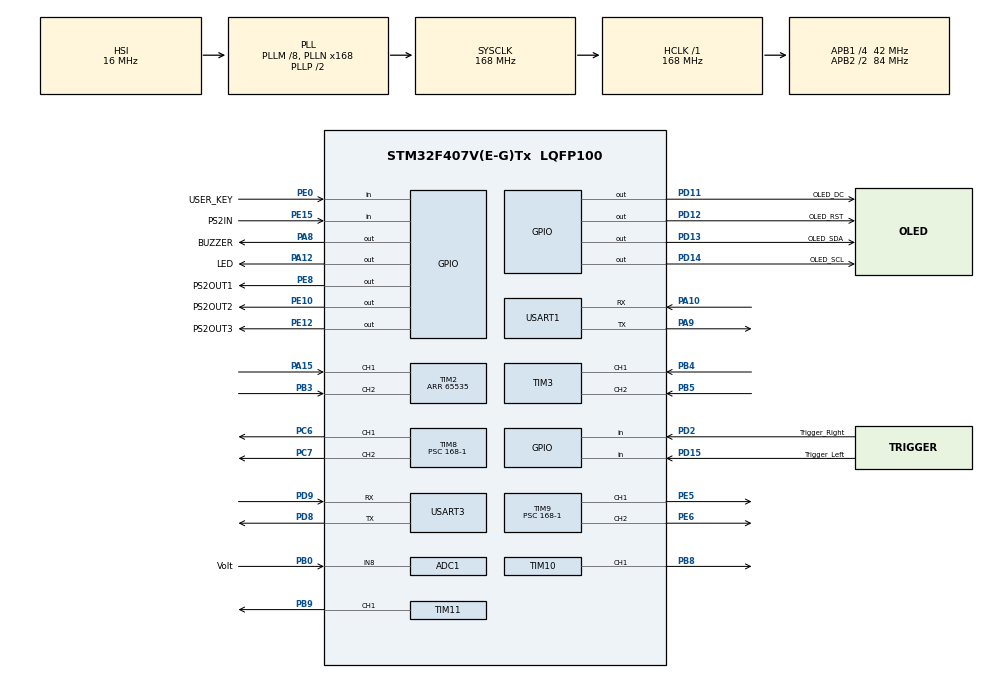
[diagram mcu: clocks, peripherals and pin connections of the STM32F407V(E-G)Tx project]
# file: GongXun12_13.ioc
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ADC1.Channel-0\#ChannelRegularConversion=ADC_CHANNEL_8
ADC1.Channel-1\#ChannelInjectedConversion=ADC_CHANNEL_8
ADC1.ContinuousConvMode=ENABLE
ADC1.InjNumberOfConversion=1
ADC1.InjectedOffset-1\#ChannelInjectedConversion=0
ADC1.InjectedRank-1\#ChannelInjectedConversion=1
ADC1.NbrOfConversion=1
ADC1.NbrOfConversionFlag=1
ADC1.Rank-0\#ChannelRegularConversion=1
ADC1.SamplingTime-0\#ChannelRegularConversion=ADC_SAMPLETIME_3CYCLES
ADC1.SamplingTime-1\#ChannelInjectedConversion=ADC_SAMPLETIME_3CYCLES
ADC1.master=1
Mcu.Family=STM32F4
Mcu.Name=STM32F407V(E-G)Tx
Mcu.Package=LQFP100
NVIC.PriorityGroup=NVIC_PRIORITYGROUP_4
NVIC.TIM1_UP_TIM10_IRQn=true\:15\:0\:false\:false\:true\:false\:true\:true
NVIC.TimeBase=TIM1_UP_TIM10_IRQn
NVIC.TimeBaseIP=TIM1
NVIC.USART1_IRQn=true\:0\:0\:false\:false\:true\:true\:true\:true
NVIC.USART3_IRQn=true\:0\:0\:false\:false\:true\:true\:true\:true
PA10.Mode=Asynchronous
PA10.Signal=USART1_RX
PA12.GPIO_Label=LED
PA12.Signal=GPIO_Output
PA13.Mode=Serial_Wire
PA13.Signal=SYS_JTMS-SWDIO
PA14.Mode=Serial_Wire
PA14.Signal=SYS_JTCK-SWCLK
PA15.Signal=S_TIM2_CH1_ETR
PA8.GPIO_Label=BUZZER
PA8.Signal=GPIO_Output
PA9.Mode=Asynchronous
PA9.Signal=USART1_TX
PB0.GPIO_Label=Volt
PB0.Signal=ADCx_IN8
PB3.Signal=S_TIM2_CH2
PB4.Signal=S_TIM3_CH1
PB5.Signal=S_TIM3_CH2
PB8.Signal=S_TIM10_CH1
PB9.Signal=S_TIM11_CH1
PC6.Signal=S_TIM8_CH1
PC7.Signal=S_TIM8_CH2
PD11.GPIO_Label=OLED_DC
PD11.Signal=GPIO_Output
PD12.GPIO_Label=OLED_RST
PD12.Signal=GPIO_Output
PD13.GPIO_Label=OLED_SDA
PD13.Signal=GPIO_Output
PD14.GPIO_Label=OLED_SCL
PD14.Signal=GPIO_Output
PD15.GPIO_Label=Trigger_Left
PD15.GPIO_PuPd=GPIO_PULLUP
PD15.Signal=GPIO_Input
PD2.GPIO_Label=Trigger_Right
PD2.GPIO_PuPd=GPIO_PULLUP
PD2.Signal=GPIO_Input
PD8.Mode=Asynchronous
PD8.Signal=USART3_TX
PD9.Mode=Asynchronous
PD9.Signal=USART3_RX
PE0.GPIO_Label=USER_KEY
PE0.Signal=GPIO_Input
PE10.GPIO_Label=PS2OUT2
PE10.GPIO_PuPd=GPIO_PULLUP
PE10.GPIO_Speed=GPIO_SPEED_FREQ_HIGH
PE10.Signal=GPIO_Output
PE12.GPIO_Label=PS2OUT3
PE12.GPIO_PuPd=GPIO_PULLUP
PE12.GPIO_Speed=GPIO_SPEED_FREQ_HIGH
PE12.Signal=GPIO_Output
PE15.GPIO_Label=PS2IN
PE15.GPIO_PuPd=GPIO_PULLDOWN
PE15.Signal=GPIO_Input
PE5.Signal=S_TIM9_CH1
PE6.Signal=S_TIM9_CH2
PE8.GPIO_Label=PS2OUT1
PE8.GPIO_PuPd=GPIO_PULLUP
PE8.GPIO_Speed=GPIO_SPEED_FREQ_HIGH
PE8.Signal=GPIO_Output
PH0-OSC_IN.Mode=HSE-External-Oscillator
PH0-OSC_IN.Signal=RCC_OSC_IN
PH1-OSC_OUT.Mode=HSE-External-Oscillator
PH1-OSC_OUT.Signal=RCC_OSC_OUT
ProjectManager.HeapSize=0x200
ProjectManager.StackSize=0x400
ProjectManager.TargetToolchain=CMake
RCC.48MHZClocksFreq_Value=84000000
RCC.AHBFreq_Value=168000000
RCC.APB1CLKDivider=RCC_HCLK_DIV4
RCC.APB1Freq_Value=42000000
RCC.APB1TimFreq_Value=84000000
RCC.APB2CLKDivider=RCC_HCLK_DIV2
RCC.APB2Freq_Value=84000000
RCC.APB2TimFreq_Value=168000000
RCC.CortexFreq_Value=168000000
RCC.HCLKFreq_Value=168000000
RCC.HSE_VALUE=25000000
RCC.HSI_VALUE=16000000
RCC.LSE_VALUE=32768
RCC.PLLM=8
RCC.PLLN=168
RCC.SYSCLKFreq_VALUE=168000000
RCC.SYSCLKSource=RCC_SYSCLKSOURCE_PLLCLK
RCC.VCOOutputFreq_Value=336000000
SH.ADCx_IN8.0=ADC1_IN8,IN8
SH.S_TIM10_CH1.0=TIM10_CH1,PWM Generation1 CH1
SH.S_TIM11_CH1.0=TIM11_CH1,PWM Generation1 CH1
SH.S_TIM2_CH1_ETR.0=TIM2_CH1,Encoder_Interface
SH.S_TIM2_CH2.0=TIM2_CH2,Encoder_Interface
SH.S_TIM3_CH1.0=TIM3_CH1,Encoder_Interface
SH.S_TIM3_CH2.0=TIM3_CH2,Encoder_Interface
SH.S_TIM8_CH1.0=TIM8_CH1,PWM Generation1 CH1
SH.S_TIM8_CH2.0=TIM8_CH2,PWM Generation2 CH2
SH.S_TIM9_CH1.0=TIM9_CH1,PWM Generation1 CH1
SH.S_TIM9_CH2.0=TIM9_CH2,PWM Generation2 CH2
TIM10.Channel=TIM_CHANNEL_1
TIM10.Period=10000-1
TIM10.Prescaler=168-1
TIM11.Channel=TIM_CHANNEL_1
TIM11.Period=10000-1
TIM11.Prescaler=168-1
TIM2.Period=65535
TIM8.Channel-PWM\ Generation1\ CH1=TIM_CHANNEL_1
TIM8.Channel-PWM\ Generation2\ CH2=TIM_CHANNEL_2
TIM8.Period=20000-1
TIM8.Prescaler=168-1
TIM9.Channel-PWM\ Generation1\ CH1=TIM_CHANNEL_1
TIM9.Channel-PWM\ Generation2\ CH2=TIM_CHANNEL_2
TIM9.Period=10000-1
TIM9.Prescaler=168-1
USART1.VirtualMode=VM_ASYNC
USART3.VirtualMode=VM_ASYNC
VP_SYS_VS_tim1.Mode=TIM1
VP_TIM10_VS_ClockSourceINT.Mode=Enable_Timer
VP_TIM11_VS_ClockSourceINT.Mode=Enable_Timer
board=custom

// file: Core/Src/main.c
/* USER CODE BEGIN Header */
/**
  ******************************************************************************
  * @file           : main.c
  * @brief          : Main program body
  ******************************************************************************
  * @attention
  *
  * Copyright (c) 2024 STMicroelectronics.
  * All rights reserved.
  *
  * This software is licensed under terms that can be found in the LICENSE file
  * in the root directory of this software component.
  * If no LICENSE file comes with this software, it is provided AS-IS.
  *
  ******************************************************************************
  */
/* USER CODE END Header */
#include "main.h"
#include "adc.h"
#include "tim.h"
#include "usart.h"
#include "gpio.h"

/* USER CODE BEGIN Includes */
#include "System.h"
#include "Delay.h"
#include "pstwo.h"
#include "motor.h"
#include "Raspi.h"
#include "servo.h"
/* USER CODE END Includes */

void SystemClock_Config(void);

int main(void)
{

  /* MCU Configuration--------------------------------------------------------*/

  /* Reset of all peripherals, Initializes the Flash interface and the Systick. */
  HAL_Init();

  /* Configure the system clock */
  SystemClock_Config();

  /* Initialize all configured peripherals */
  MX_GPIO_Init();
  MX_TIM2_Init();
  MX_TIM3_Init();
  MX_TIM9_Init();
  MX_TIM10_Init();
  MX_TIM11_Init();
  MX_USART1_UART_Init();
  MX_USART3_UART_Init();
  MX_ADC1_Init();
  MX_TIM8_Init();

  /* Infinite loop */
  /* USER CODE BEGIN WHILE */
  usDelayInit();//微秒级延时初始化
  Car_Init();//小车电机初始�??
  USART_Init();//串口初始�??
  PS2_SetInit();//PS2初始�??
  Servo_init();
  Task_Init();//任务初始�??
  while (1)
  {
    /* USER CODE END WHILE */

  }
}

void SystemClock_Config(void)
{
  RCC_OscInitTypeDef RCC_OscInitStruct = {0};
  RCC_ClkInitTypeDef RCC_ClkInitStruct = {0};

  /** Configure the main internal regulator output voltage
  */
  __HAL_RCC_PWR_CLK_ENABLE();
  __HAL_PWR_VOLTAGESCALING_CONFIG(PWR_REGULATOR_VOLTAGE_SCALE1);

  /** Initializes the RCC Oscillators according to the specified parameters
  * in the RCC_OscInitTypeDef structure.
  */
  RCC_OscInitStruct.OscillatorType = RCC_OSCILLATORTYPE_HSI;
  RCC_OscInitStruct.HSIState = RCC_HSI_ON;
  RCC_OscInitStruct.HSICalibrationValue = RCC_HSICALIBRATION_DEFAULT;
  RCC_OscInitStruct.PLL.PLLState = RCC_PLL_ON;
  RCC_OscInitStruct.PLL.PLLSource = RCC_PLLSOURCE_HSI;
  RCC_OscInitStruct.PLL.PLLM = 8;
  RCC_OscInitStruct.PLL.PLLN = 168;
  RCC_OscInitStruct.PLL.PLLP = RCC_PLLP_DIV2;
  RCC_OscInitStruct.PLL.PLLQ = 4;
  if (HAL_RCC_OscConfig(&RCC_OscInitStruct) != HAL_OK)
  {
    Error_Handler();
  }

  /** Initializes the CPU, AHB and APB buses clocks
  */
  RCC_ClkInitStruct.ClockType = RCC_CLOCKTYPE_HCLK|RCC_CLOCKTYPE_SYSCLK
                              |RCC_CLOCKTYPE_PCLK1|RCC_CLOCKTYPE_PCLK2;
  RCC_ClkInitStruct.SYSCLKSource = RCC_SYSCLKSOURCE_PLLCLK;
  RCC_ClkInitStruct.AHBCLKDivider = RCC_SYSCLK_DIV1;
  RCC_ClkInitStruct.APB1CLKDivider = RCC_HCLK_DIV4;
  RCC_ClkInitStruct.APB2CLKDivider = RCC_HCLK_DIV2;

  if (HAL_RCC_ClockConfig(&RCC_ClkInitStruct, FLASH_LATENCY_5) != HAL_OK)
  {
    Error_Handler();
  }
}

void HAL_TIM_PeriodElapsedCallback(TIM_HandleTypeDef *htim)
{
  if (htim->Instance == TIM1) {
    HAL_IncTick();
  }
}

void Error_Handler(void)
{
  __disable_irq();
  while (1)
  {
  }
}
